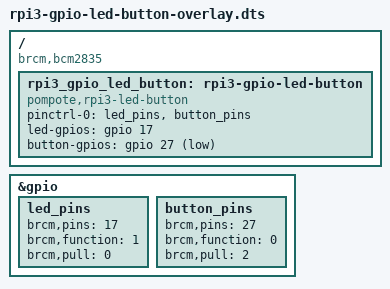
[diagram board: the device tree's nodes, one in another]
// SPDX-License-Identifier: GPL-2.0-only
/*
 * Device Tree overlay adding the node consumed by rpi3_gpio_driver.ko.
 *
 * Wiring (BCM numbering):
 *   - GPIO17 (physical pin 11) -> 330ohm resistor -> LED anode
 *     LED cathode -> GND (physical pin 9)
 *   - GPIO27 (physical pin 13) -> push button -> GND (physical pin 14)
 *     Internal pull-up enabled below: idle = high, pressed = pulled low,
 *     which is why button-gpios is flagged GPIO_ACTIVE_LOW.
 */

/dts-v1/;
/plugin/;

#include <dt-bindings/gpio/gpio.h>

/ {
	/*
	 * Same compatible string used by upstream RPi overlays for plain
	 * GPIO/pinctrl fragments: the BCM2837 (Pi3) reuses the BCM2835
	 * GPIO controller IP unchanged.
	 */
	compatible = "brcm,bcm2835";

	fragment@0 {
		target-path = "/";
		__overlay__ {
			rpi3_gpio_led_button: rpi3-gpio-led-button {
				/*
				 * "pompote" is a placeholder vendor prefix
				 * (that's me lol), not a
				 * registered dt-bindings vendor prefix. It's fine
				 * for an out-of-tree overlay, but would need
				 * changing before any upstream submission.
				 */
				compatible = "pompote,rpi3-led-button";
				pinctrl-names = "default";
				pinctrl-0 = <&led_pins>, <&button_pins>;

				led-gpios = <&gpio 17 GPIO_ACTIVE_HIGH>;
				button-gpios = <&gpio 27 GPIO_ACTIVE_LOW>;

				status = "okay";
			};
		};
	};

	fragment@1 {
		target = <&gpio>;
		__overlay__ {
			led_pins: led_pins {
				brcm,pins = <17>;
				brcm,function = <1>; /* 1 = output */
				brcm,pull = <0>;     /* 0 = no pull */
			};

			button_pins: button_pins {
				brcm,pins = <27>;
				brcm,function = <0>; /* 0 = input */
				brcm,pull = <2>;     /* 2 = pull-up */
			};
		};
	};
};
